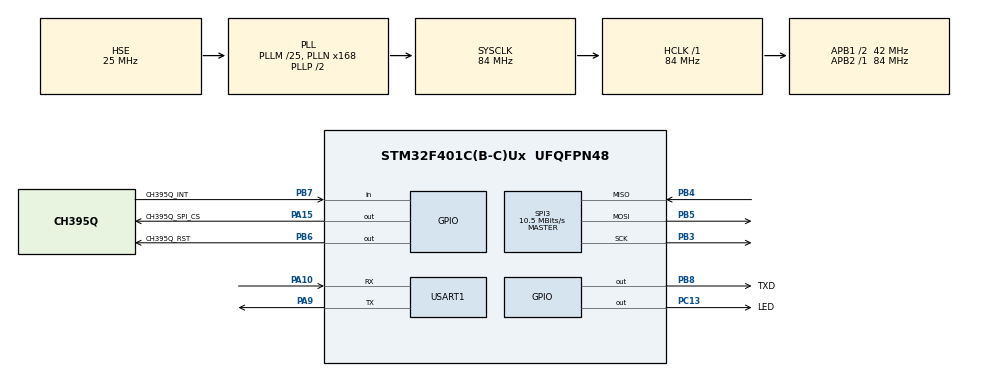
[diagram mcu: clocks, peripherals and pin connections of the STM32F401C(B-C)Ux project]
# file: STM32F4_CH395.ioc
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Mcu.Family=STM32F4
Mcu.Name=STM32F401C(B-C)Ux
Mcu.Package=UFQFPN48
NVIC.PriorityGroup=NVIC_PRIORITYGROUP_4
PA10.Mode=Asynchronous
PA10.Signal=USART1_RX
PA13.Mode=Serial_Wire
PA13.Signal=SYS_JTMS-SWDIO
PA14.Mode=Serial_Wire
PA14.Signal=SYS_JTCK-SWCLK
PA15.GPIO_Label=CH395Q_SPI_CS
PA15.GPIO_ModeDefaultOutputPP=GPIO_MODE_OUTPUT_PP
PA15.GPIO_PuPd=GPIO_PULLUP
PA15.GPIO_Speed=GPIO_SPEED_FREQ_VERY_HIGH
PA15.PinState=GPIO_PIN_SET
PA15.Signal=GPIO_Output
PA9.Mode=Asynchronous
PA9.Signal=USART1_TX
PB3.Mode=Full_Duplex_Master
PB3.Signal=SPI3_SCK
PB4.Mode=Full_Duplex_Master
PB4.Signal=SPI3_MISO
PB5.Mode=Full_Duplex_Master
PB5.Signal=SPI3_MOSI
PB6.GPIO_Label=CH395Q_RST
PB6.GPIO_ModeDefaultOutputPP=GPIO_MODE_OUTPUT_PP
PB6.GPIO_PuPd=GPIO_PULLUP
PB6.GPIO_Speed=GPIO_SPEED_FREQ_VERY_HIGH
PB6.PinState=GPIO_PIN_SET
PB6.Signal=GPIO_Output
PB7.GPIO_Label=CH395Q_INT
PB7.GPIO_PuPd=GPIO_PULLUP
PB7.Signal=GPIO_Input
PB8.GPIO_Label=TXD
PB8.GPIO_ModeDefaultOutputPP=GPIO_MODE_OUTPUT_PP
PB8.GPIO_PuPd=GPIO_PULLDOWN
PB8.GPIO_Speed=GPIO_SPEED_FREQ_VERY_HIGH
PB8.PinState=GPIO_PIN_RESET
PB8.Signal=GPIO_Output
PC13-ANTI_TAMP.GPIO_Label=LED
PC13-ANTI_TAMP.GPIO_ModeDefaultOutputPP=GPIO_MODE_OUTPUT_PP
PC13-ANTI_TAMP.GPIO_PuPd=GPIO_PULLUP
PC13-ANTI_TAMP.PinState=GPIO_PIN_SET
PC13-ANTI_TAMP.Signal=GPIO_Output
PC14-OSC32_IN.Mode=LSE-External-Oscillator
PC14-OSC32_IN.Signal=RCC_OSC32_IN
PC15-OSC32_OUT.Mode=LSE-External-Oscillator
PC15-OSC32_OUT.Signal=RCC_OSC32_OUT
PH0\ -\ OSC_IN.Mode=HSE-External-Oscillator
PH0\ -\ OSC_IN.Signal=RCC_OSC_IN
PH1\ -\ OSC_OUT.Mode=HSE-External-Oscillator
PH1\ -\ OSC_OUT.Signal=RCC_OSC_OUT
ProjectManager.HeapSize=0x200
ProjectManager.StackSize=0x400
ProjectManager.TargetToolchain=MDK-ARM V5.27
RCC.48MHZClocksFreq_Value=42000000
RCC.AHBFreq_Value=84000000
RCC.APB1CLKDivider=RCC_HCLK_DIV2
RCC.APB1Freq_Value=42000000
RCC.APB1TimFreq_Value=84000000
RCC.APB2Freq_Value=84000000
RCC.APB2TimFreq_Value=84000000
RCC.CortexFreq_Value=84000000
RCC.HCLKFreq_Value=84000000
RCC.HSE_VALUE=25000000
RCC.HSI_VALUE=16000000
RCC.PLLM=25
RCC.PLLN=168
RCC.PLLSourceVirtual=RCC_PLLSOURCE_HSE
RCC.SYSCLKFreq_VALUE=84000000
RCC.SYSCLKSource=RCC_SYSCLKSOURCE_PLLCLK
RCC.VCOOutputFreq_Value=168000000
SPI3.BaudRatePrescaler=SPI_BAUDRATEPRESCALER_4
SPI3.CalculateBaudRate=10.5 MBits/s
SPI3.Direction=SPI_DIRECTION_2LINES
SPI3.Mode=SPI_MODE_MASTER
SPI3.VirtualType=VM_MASTER
USART1.VirtualMode=VM_ASYNC
board=custom

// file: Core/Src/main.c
/* USER CODE BEGIN Header */
/**
  ******************************************************************************
  * @file           : main.c
  * @brief          : Main program body
  ******************************************************************************
  * @attention
  *
  * <h2><center>&copy; Copyright (c) 2023 STMicroelectronics.
  * All rights reserved.</center></h2>
  *
  * This software component is licensed by ST under BSD 3-Clause license,
  * the "License"; You may not use this file except in compliance with the
  * License. You may obtain a copy of the License at:
  *                        opensource.org/licenses/BSD-3-Clause
  *
  ******************************************************************************
  */
/* USER CODE END Header */
#include "main.h"
#include "spi.h"
#include "usart.h"
#include "gpio.h"

/* USER CODE BEGIN Includes */
#include "stdio.h"
#include "string.h"
#include "demo.h"
/* USER CODE END Includes */

void SystemClock_Config(void);

int main(void)
{

  /* MCU Configuration--------------------------------------------------------*/

  /* Reset of all peripherals, Initializes the Flash interface and the Systick. */
  HAL_Init();

  /* Configure the system clock */
  SystemClock_Config();

  /* Initialize all configured peripherals */
  MX_GPIO_Init();
  MX_SPI3_Init();
  MX_USART1_UART_Init();
  /* USER CODE BEGIN 2 */
	printf("hello world!\r\n");
  /* USER CODE END 2 */

  /* Infinite loop */
  /* USER CODE BEGIN WHILE */
  while (1)
  {
		demo_run();
    /* USER CODE END WHILE */

  }
}

void SystemClock_Config(void)
{
  RCC_OscInitTypeDef RCC_OscInitStruct = {0};
  RCC_ClkInitTypeDef RCC_ClkInitStruct = {0};

  /** Configure the main internal regulator output voltage
  */
  __HAL_RCC_PWR_CLK_ENABLE();
  __HAL_PWR_VOLTAGESCALING_CONFIG(PWR_REGULATOR_VOLTAGE_SCALE2);
  /** Initializes the RCC Oscillators according to the specified parameters
  * in the RCC_OscInitTypeDef structure.
  */
  RCC_OscInitStruct.OscillatorType = RCC_OSCILLATORTYPE_HSE;
  RCC_OscInitStruct.HSEState = RCC_HSE_ON;
  RCC_OscInitStruct.PLL.PLLState = RCC_PLL_ON;
  RCC_OscInitStruct.PLL.PLLSource = RCC_PLLSOURCE_HSE;
  RCC_OscInitStruct.PLL.PLLM = 25;
  RCC_OscInitStruct.PLL.PLLN = 168;
  RCC_OscInitStruct.PLL.PLLP = RCC_PLLP_DIV2;
  RCC_OscInitStruct.PLL.PLLQ = 4;
  if (HAL_RCC_OscConfig(&RCC_OscInitStruct) != HAL_OK)
  {
    Error_Handler();
  }
  /** Initializes the CPU, AHB and APB buses clocks
  */
  RCC_ClkInitStruct.ClockType = RCC_CLOCKTYPE_HCLK|RCC_CLOCKTYPE_SYSCLK
                              |RCC_CLOCKTYPE_PCLK1|RCC_CLOCKTYPE_PCLK2;
  RCC_ClkInitStruct.SYSCLKSource = RCC_SYSCLKSOURCE_PLLCLK;
  RCC_ClkInitStruct.AHBCLKDivider = RCC_SYSCLK_DIV1;
  RCC_ClkInitStruct.APB1CLKDivider = RCC_HCLK_DIV2;
  RCC_ClkInitStruct.APB2CLKDivider = RCC_HCLK_DIV1;

  if (HAL_RCC_ClockConfig(&RCC_ClkInitStruct, FLASH_LATENCY_2) != HAL_OK)
  {
    Error_Handler();
  }
}

/* USER CODE BEGIN 4 */
	int fputc(int ch,FILE *f)
	{
			HAL_UART_Transmit(&huart1 , (uint8_t *)&ch , 1 , 0xffff);
			return ch;
	}
/* USER CODE END 4 */

void Error_Handler(void)
{
  __disable_irq();
  while (1)
  {
  }
}

/************************ (C) COPYRIGHT STMicroelectronics *****END OF FILE****/
